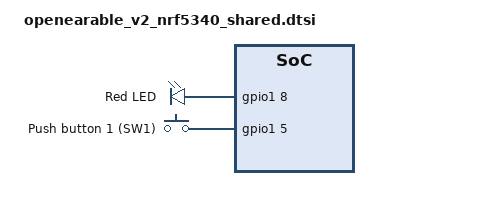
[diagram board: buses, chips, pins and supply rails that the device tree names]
#include <zephyr/dt-bindings/input/input-event-codes.h>

/ {
	
	leds {
		compatible = "gpio-leds";
		led_error: led_error {
			gpios = <&gpio1 8 GPIO_ACTIVE_HIGH>;
			label = "Red LED";
		};
	};

	/*leds {
		 compatible = "gpio-leds";
		 led0: led_0 {
			 gpios = <&gpio0 28 GPIO_ACTIVE_LOW>;
			 label = "Green LED 0";
		 };
		 led1: led_1 {
			 gpios = <&gpio0 30 GPIO_ACTIVE_LOW>;
			 label = "Red LED 1";
		 };
		 led2: led_2 {
			 gpios = <&gpio0 31 GPIO_ACTIVE_LOW>;
			 label = "LED 2";
		 };
		 led3: led_3 {
			 gpios = <&gpio0 29 GPIO_ACTIVE_LOW>;
			 label = "LED 3";
		 };
	 };
 
	 pwmleds {
		 compatible = "pwm-leds";
		 pwm_led0: pwm_led_0 {
			 pwms = <&pwm0 0 PWM_MSEC(20) PWM_POLARITY_INVERTED>;
		 };
	 };*/

	buttons {
		compatible = "gpio-keys";
		button0: button_0 {
			gpios = <&gpio1 5 (GPIO_PULL_DOWN | GPIO_ACTIVE_HIGH)>;
			label = "Push button 1 (SW1)";
			zephyr,code = <INPUT_KEY_0>;
		};
		/*button1: button_1 {
			gpios = <&gpio0 8 (GPIO_PULL_UP | GPIO_ACTIVE_LOW)>;
			label = "Push button 2 (SW2)";
			zephyr,code = <INPUT_KEY_1>;
		};
		button2: button_2 {
			gpios = <&gpio0 23 (GPIO_PULL_UP | GPIO_ACTIVE_LOW)>;
			label = "Push button 3 (SW3)";
			zephyr,code = <INPUT_KEY_2>;
		};
		button3: button_3 {
			gpios = <&gpio0 9 (GPIO_PULL_UP | GPIO_ACTIVE_LOW)>;
			label = "Push button 4 (SW4)";
			zephyr,code = <INPUT_KEY_3>;
		};*/
	};

	/* These aliases are provided for compatibility with samples */
	aliases {
		/*led0 = &led0;
		led1 = &led1;
		led2 = &led2;
		led3 = &led3;
		pwm-led0 = &pwm_led0;*/
		sw0 = &button0;
		/*sw1 = &button1;
		sw2 = &button2;
		sw3 = &button3;*/
		//bootloader-led0 = &led0;
		mcuboot-button0 = &button0;
		mcuboot-led0 = &led_error;
		watchdog0 = &wdt0;
	};
};
